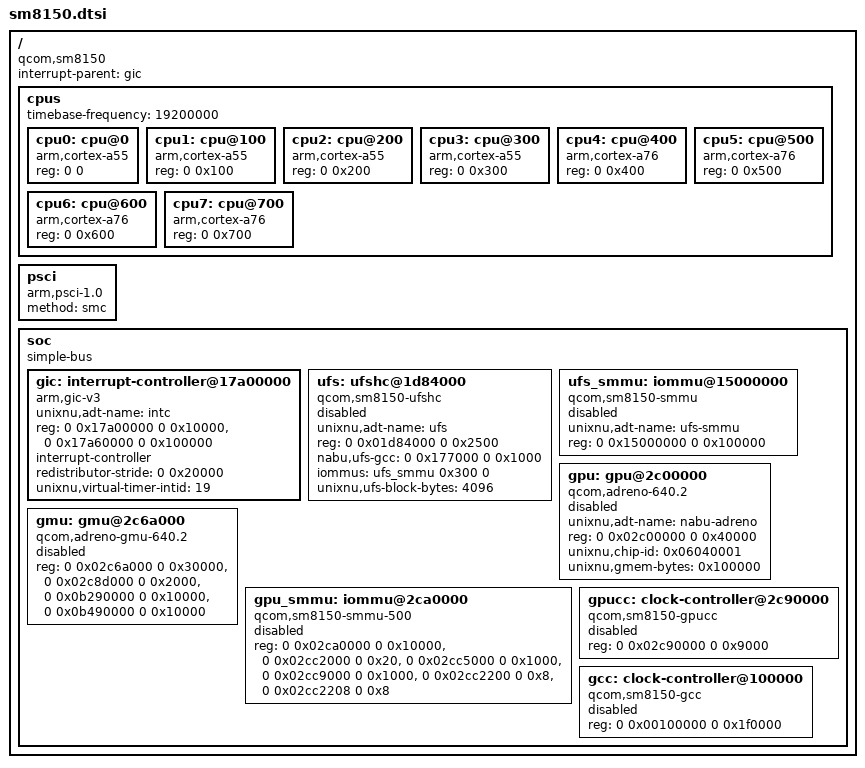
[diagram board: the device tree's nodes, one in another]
// SPDX-License-Identifier: BSD-2-Clause-Patent
// SM8150 hardware description for UniXNU boards. Register windows are taken
// from the Xiaomi Pad 5 (nabu) firmware device tree and the SM8150 mainline
// reference pinned in soc.toml. Board DTS files enable the nodes they use.
/ {
    compatible = "qcom,sm8150";
    #address-cells = <2>;
    #size-cells = <2>;
    interrupt-parent = <&gic>;

    cpus {
        #address-cells = <2>;
        #size-cells = <0>;
        // MPIDR affinity 0x000-0x700; 19.2 MHz architected counter.
        timebase-frequency = <19200000>;
        // 4x Kryo 485 Silver (Cortex-A55 derived)
        cpu0: cpu@0 { device_type = "cpu"; compatible = "arm,cortex-a55"; reg = <0 0>; };
        cpu1: cpu@100 { device_type = "cpu"; compatible = "arm,cortex-a55"; reg = <0 0x100>; };
        cpu2: cpu@200 { device_type = "cpu"; compatible = "arm,cortex-a55"; reg = <0 0x200>; };
        cpu3: cpu@300 { device_type = "cpu"; compatible = "arm,cortex-a55"; reg = <0 0x300>; };
        // 3x Kryo 485 Gold (Cortex-A76 derived)
        cpu4: cpu@400 { device_type = "cpu"; compatible = "arm,cortex-a76"; reg = <0 0x400>; };
        cpu5: cpu@500 { device_type = "cpu"; compatible = "arm,cortex-a76"; reg = <0 0x500>; };
        cpu6: cpu@600 { device_type = "cpu"; compatible = "arm,cortex-a76"; reg = <0 0x600>; };
        // 1x Kryo 485 Prime (Cortex-A76 derived)
        cpu7: cpu@700 { device_type = "cpu"; compatible = "arm,cortex-a76"; reg = <0 0x700>; };
    };

    psci { compatible = "arm,psci-1.0"; method = "smc"; };

    soc {
        compatible = "simple-bus";
        #address-cells = <2>;
        #size-cells = <2>;
        // XNU ArmCpu maps the child bus window [0,0x08000000) onto the parent
        // MMIO range [0x17000000,0x1f000000).
        ranges = <0 0x17000000 0x0 0x17000000 0x0 0x08000000>;

        gic: interrupt-controller@17a00000 {
            compatible = "arm,gic-v3";
            unixnu,adt-name = "intc";
            reg = <0 0x17a00000 0 0x10000>, <0 0x17a60000 0 0x100000>;
            #interrupt-cells = <4>;
            #address-cells = <0>;
            interrupt-controller;
            redistributor-stride = <0 0x20000>;
            // Virtual timer interrupt verified on hardware: INTID 19.
            unixnu,virtual-timer-intid = <19>;
        };

        ufs: ufshc@1d84000 {
            compatible = "qcom,sm8150-ufshc";
            unixnu,adt-name = "ufs";
            reg = <0 0x01d84000 0 0x2500>;
            // Board resource windows used by the UniXNU NativeUfs provider.
            nabu,ufs-gcc = <0 0x177000 0 0x1000>;
            iommus = <&ufs_smmu 0x300 0>;
            unixnu,ufs-block-bytes = <4096>;
            status = "disabled";
        };

        ufs_smmu: iommu@15000000 {
            compatible = "qcom,sm8150-smmu", "arm,smmu-v2";
            unixnu,adt-name = "ufs-smmu";
            reg = <0 0x15000000 0 0x100000>;
            #iommu-cells = <2>;
            status = "disabled";
        };

        gpu: gpu@2c00000 {
            compatible = "qcom,adreno-640.2", "qcom,adreno";
            unixnu,adt-name = "nabu-adreno";
            reg = <0 0x02c00000 0 0x40000>;
            reg-names = "kgsl_3d0_reg_memory";
            // chip-id 0x06040001 = Adreno640v2; GMEM is 1 MiB.
            unixnu,chip-id = <0x06040001>;
            unixnu,gmem-bytes = <0x100000>;
            status = "disabled";
        };

        gmu: gmu@2c6a000 {
            compatible = "qcom,adreno-gmu-640.2", "qcom,adreno-gmu";
            reg = <0 0x02c6a000 0 0x30000>, <0 0x02c8d000 0 0x2000>,
                  <0 0x0b290000 0 0x10000>, <0 0x0b490000 0 0x10000>;
            reg-names = "gmu", "rscc", "gmu_pdc", "gmu_pdc_seq";
            status = "disabled";
        };

        gpu_smmu: iommu@2ca0000 {
            compatible = "qcom,sm8150-smmu-500", "qcom,adreno-smmu", "arm,mmu-500";
            reg = <0 0x02ca0000 0 0x10000>,
                  <0 0x02cc2000 0 0x20>,     // tcu
                  <0 0x02cc5000 0 0x1000>,   // tbu-0
                  <0 0x02cc9000 0 0x1000>,   // tbu-1
                  <0 0x02cc2200 0 0x8>,      // tbu-0 status
                  <0 0x02cc2208 0 0x8>;      // tbu-1 status
            #iommu-cells = <2>;
            status = "disabled";
        };

        gpucc: clock-controller@2c90000 {
            compatible = "qcom,sm8150-gpucc";
            reg = <0 0x02c90000 0 0x9000>;
            status = "disabled";
        };

        gcc: clock-controller@100000 {
            compatible = "qcom,sm8150-gcc";
            reg = <0 0x00100000 0 0x1f0000>;
            status = "disabled";
        };
    };
};
